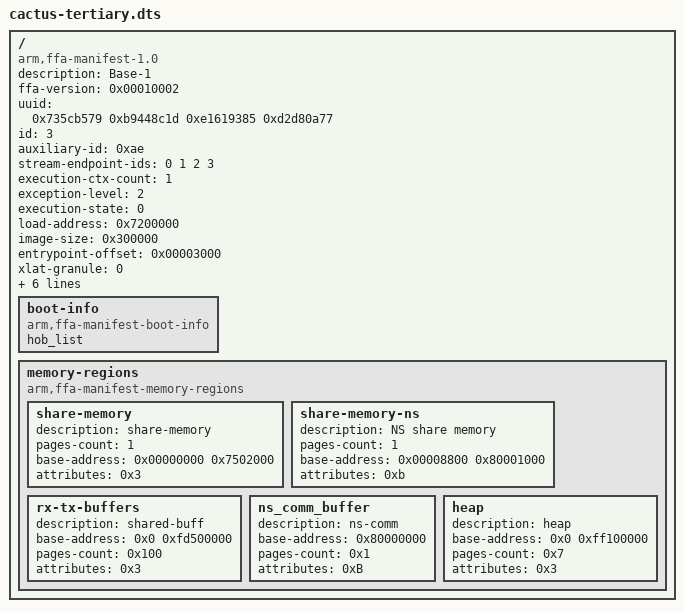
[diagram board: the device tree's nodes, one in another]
/*
 * Copyright (c) 2020-2023, Arm Limited. All rights reserved.
 *
 * SPDX-License-Identifier: BSD-3-Clause
 *
 * This file is a Partition Manifest (PM) for a minimal Secure Partition (SP)
 * that has additional optional properties defined.
 *
 */

/dts-v1/;

/ {
	compatible = "arm,ffa-manifest-1.0";

	/* Properties */
	description = "Base-1";
	ffa-version = <0x00010002>; /* 31:16 - Major, 15:0 - Minor */
	uuid = <0x735cb579 0xb9448c1d 0xe1619385 0xd2d80a77>;
	id = <3>;
	auxiliary-id = <0xae>;
	stream-endpoint-ids = <0 1 2 3>;
	execution-ctx-count = <1>;
	exception-level = <2>; /* S-EL1 */
	execution-state = <0>; /* AARCH64 */
	load-address = <0x7200000>;
	image-size = <0x300000>;
	entrypoint-offset = <0x00003000>; /*Image after manifest and HOB list. */
	xlat-granule = <0>; /* 4KiB */
	boot-order = <2>;
	notification-support;
	messaging-method = <3>; /* Direct messaging only */
	managed-exit; /* Managed exit is supported */
	managed-exit-virq;

	/* Boot protocol */
	gp-register-num = <0>;

	/* Boot Info */
	boot-info {
		compatible = "arm,ffa-manifest-boot-info";
		hob_list;
	};

	memory-regions {
		compatible = "arm,ffa-manifest-memory-regions";

		/* Memory to be shared in memory sharing tests. */
		share-memory {
			description = "share-memory";
			pages-count = <1>;
			base-address = <0x00000000 0x7502000>;
			attributes = <0x3>; /* read-write */
		};

		/* Memory to be shared in memory sharing tests. */
		share-memory-ns {
			description = "NS share memory";
			pages-count = <1>;
			base-address = <0x00008800 0x80001000>;
			attributes = <0xb>; /* NS / read-write */
		};

		/* StMM-specific region used for HOB list testing. */
		rx-tx-buffers {
			description = "shared-buff";
			base-address = <0x0 0xfd500000>;
			pages-count = <0x100>;
			attributes = <0x3>;
		};

		/* StMM-specific region used for HOB list testing. */
		ns_comm_buffer {
			/*
			 * Description is needed for StMM to identify
			 * ns-communication buffer.
			 */
			description = "ns-comm";
			base-address = <0x80000000>;
			pages-count = <0x1>;
			attributes = <0xB>;
		};

		/* StMM-specific region used for HOB list testing. */
		heap {
			/*
			 * Description is needed for StMM to identify
			 * heap buffer.
			 */
			description = "heap";
			base-address = <0x0 0xff100000>;
			pages-count = <0x7>;
			attributes = <0x3>;
		};
	};
};
